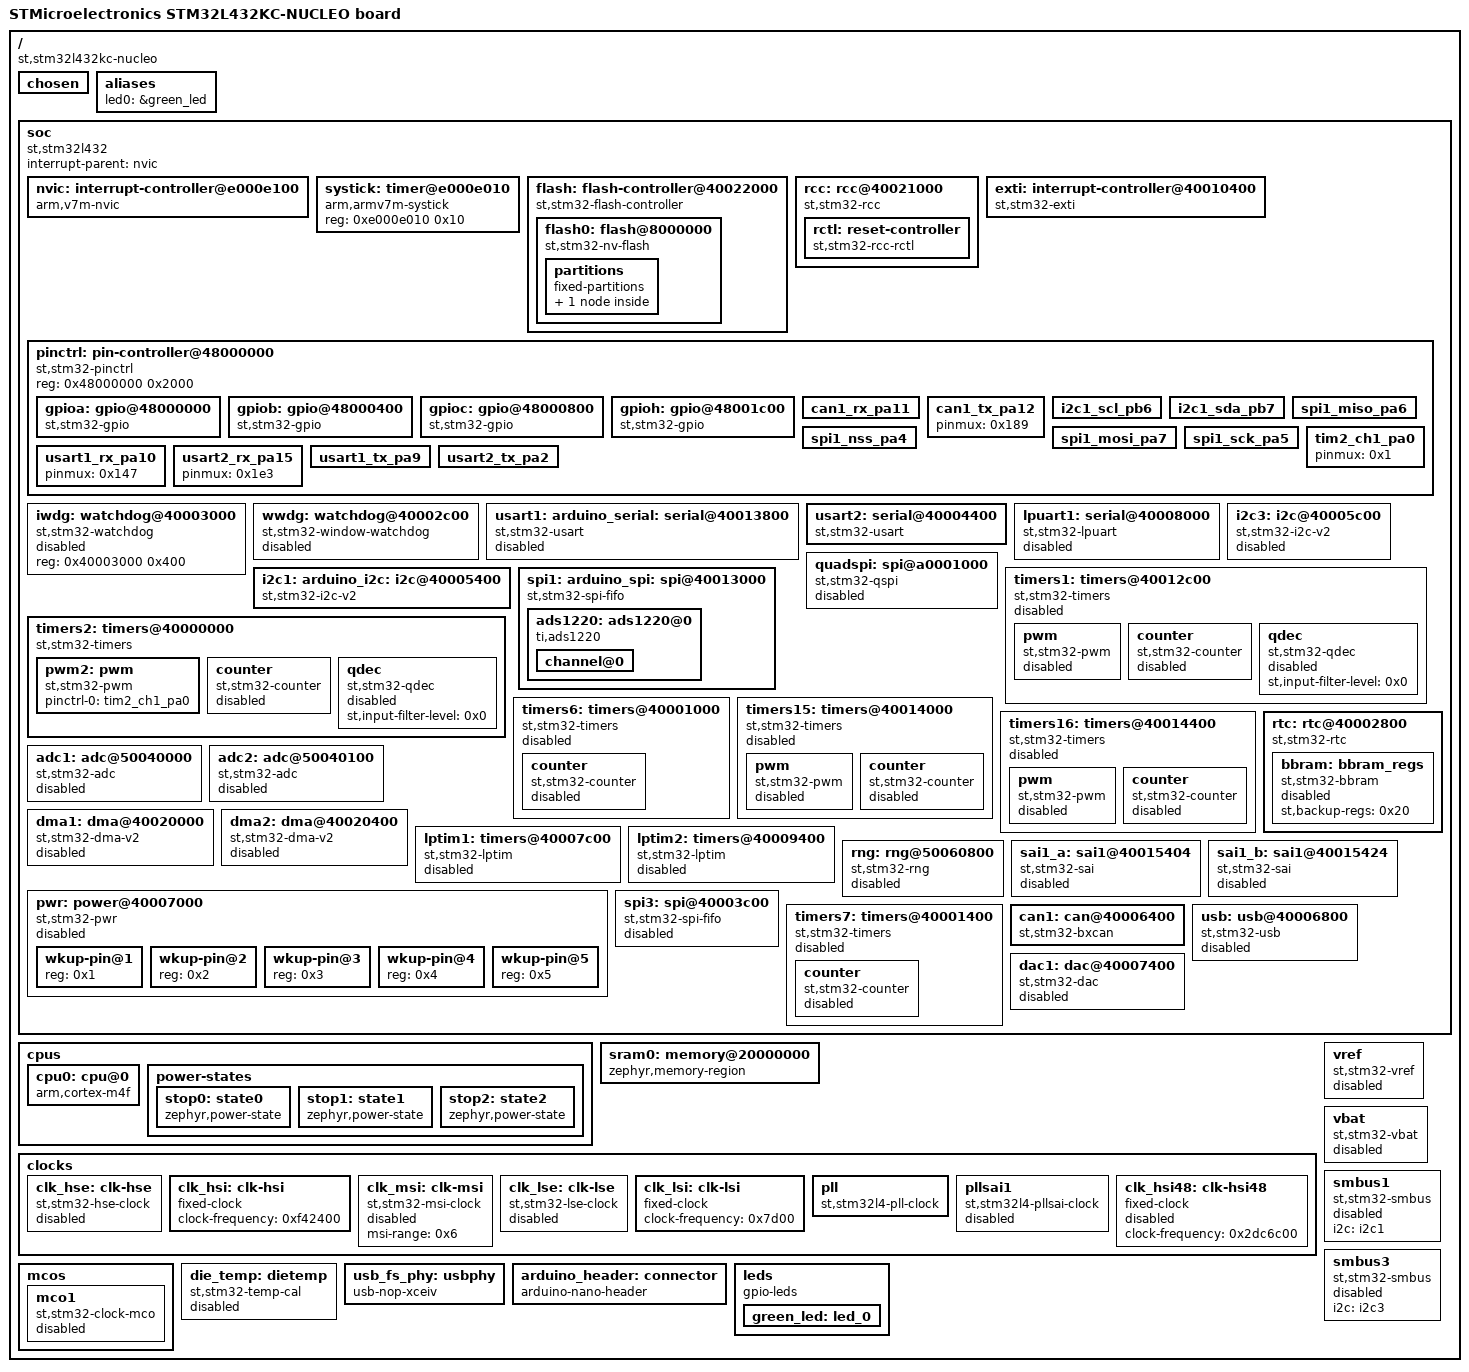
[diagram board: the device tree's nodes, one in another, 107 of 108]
/dts-v1/;

/* node '/' defined in zephyr\dts\common\skeleton.dtsi:9 */
/ {
	#address-cells = < 0x1 >;                              /* in zephyr\dts\common\skeleton.dtsi:10 */
	#size-cells = < 0x1 >;                                 /* in zephyr\dts\common\skeleton.dtsi:11 */
	model = "STMicroelectronics STM32L432KC-NUCLEO board"; /* in zephyr\boards\st\nucleo_l432kc\nucleo_l432kc.dts:13 */
	compatible = "st,stm32l432kc-nucleo";                  /* in zephyr\boards\st\nucleo_l432kc\nucleo_l432kc.dts:14 */

	/* node '/chosen' defined in zephyr\dts\common\skeleton.dtsi:13 */
	chosen {
		zephyr,entropy = &rng;            /* in zephyr\dts\arm\st\l4\stm32l4.dtsi:25 */
		zephyr,flash-controller = &flash; /* in zephyr\dts\arm\st\l4\stm32l4.dtsi:26 */
		zephyr,console = &usart2;         /* in zephyr\boards\st\nucleo_l432kc\nucleo_l432kc.dts:17 */
		zephyr,shell-uart = &usart2;      /* in zephyr\boards\st\nucleo_l432kc\nucleo_l432kc.dts:18 */
		zephyr,sram = &sram0;             /* in zephyr\boards\st\nucleo_l432kc\nucleo_l432kc.dts:19 */
		zephyr,flash = &flash0;           /* in zephyr\boards\st\nucleo_l432kc\nucleo_l432kc.dts:20 */
		zephyr,canbus = &can1;            /* in zephyr\boards\st\nucleo_l432kc\nucleo_l432kc.dts:21 */
	};

	/* node '/aliases' defined in zephyr\dts\common\skeleton.dtsi:15 */
	aliases {
		led0 = &green_led; /* in zephyr\boards\st\nucleo_l432kc\nucleo_l432kc.dts:34 */
	};

	/* node '/soc' defined in zephyr\dts\arm\armv7-m.dtsi:6 */
	soc {
		#address-cells = < 0x1 >;     /* in zephyr\dts\arm\armv7-m.dtsi:7 */
		#size-cells = < 0x1 >;        /* in zephyr\dts\arm\armv7-m.dtsi:8 */
		interrupt-parent = < &nvic >; /* in zephyr\dts\arm\armv7-m.dtsi:10 */
		ranges;                       /* in zephyr\dts\arm\armv7-m.dtsi:11 */
		compatible = "st,stm32l432",
		             "st,stm32l4",
		             "simple-bus";    /* in zephyr\dts\arm\st\l4\stm32l432.dtsi:21 */

		/* node '/soc/interrupt-controller@e000e100' defined in zephyr\dts\arm\armv7-m.dtsi:13 */
		nvic: interrupt-controller@e000e100 {
			#address-cells = < 0x1 >;            /* in zephyr\dts\arm\armv7-m.dtsi:14 */
			compatible = "arm,v7m-nvic";         /* in zephyr\dts\arm\armv7-m.dtsi:15 */
			reg = < 0xe000e100 0xc00 >;          /* in zephyr\dts\arm\armv7-m.dtsi:16 */
			interrupt-controller;                /* in zephyr\dts\arm\armv7-m.dtsi:17 */
			#interrupt-cells = < 0x2 >;          /* in zephyr\dts\arm\armv7-m.dtsi:18 */
			arm,num-irq-priority-bits = < 0x4 >; /* in zephyr\dts\arm\st\l4\stm32l4.dtsi:597 */
			phandle = < 0x1 >;                   /* in zephyr\dts\arm\armv7-m.dtsi:10 */
		};

		/* node '/soc/timer@e000e010' defined in zephyr\dts\arm\armv7-m.dtsi:21 */
		systick: timer@e000e010 {
			compatible = "arm,armv7m-systick"; /* in zephyr\dts\arm\armv7-m.dtsi:22 */
			reg = < 0xe000e010 0x10 >;         /* in zephyr\dts\arm\armv7-m.dtsi:23 */
		};

		/* node '/soc/flash-controller@40022000' defined in zephyr\dts\arm\st\l4\stm32l4.dtsi:126 */
		flash: flash-controller@40022000 {
			compatible = "st,stm32-flash-controller",
			             "st,stm32l4-flash-controller"; /* in zephyr\dts\arm\st\l4\stm32l4.dtsi:127 */
			reg = < 0x40022000 0x400 >;                 /* in zephyr\dts\arm\st\l4\stm32l4.dtsi:128 */
			interrupts = < 0x4 0x0 >;                   /* in zephyr\dts\arm\st\l4\stm32l4.dtsi:129 */
			clocks = < &rcc 0x48 0x100 >;               /* in zephyr\dts\arm\st\l4\stm32l4.dtsi:130 */
			#address-cells = < 0x1 >;                   /* in zephyr\dts\arm\st\l4\stm32l4.dtsi:132 */
			#size-cells = < 0x1 >;                      /* in zephyr\dts\arm\st\l4\stm32l4.dtsi:133 */

			/* node '/soc/flash-controller@40022000/flash@8000000' defined in zephyr\dts\arm\st\l4\stm32l4.dtsi:135 */
			flash0: flash@8000000 {
				compatible = "st,stm32-nv-flash",
				             "soc-nv-flash";      /* in zephyr\dts\arm\st\l4\stm32l4.dtsi:136 */
				write-block-size = < 0x8 >;       /* in zephyr\dts\arm\st\l4\stm32l4.dtsi:138 */
				erase-block-size = < 0x800 >;     /* in zephyr\dts\arm\st\l4\stm32l4.dtsi:139 */
				max-erase-time = < 0x19 >;        /* in zephyr\dts\arm\st\l4\stm32l4.dtsi:141 */
				reg = < 0x8000000 0x40000 >;      /* in zephyr\dts\arm\st\l4\stm32l432Xc.dtsi:16 */

				/* node '/soc/flash-controller@40022000/flash@8000000/partitions' defined in zephyr\boards\st\nucleo_l432kc\nucleo_l432kc.dts:114 */
				partitions {
					compatible = "fixed-partitions"; /* in zephyr\boards\st\nucleo_l432kc\nucleo_l432kc.dts:115 */
					#address-cells = < 0x1 >;        /* in zephyr\boards\st\nucleo_l432kc\nucleo_l432kc.dts:116 */
					#size-cells = < 0x1 >;           /* in zephyr\boards\st\nucleo_l432kc\nucleo_l432kc.dts:117 */

					/* node '/soc/flash-controller@40022000/flash@8000000/partitions/partition@3c000' defined in zephyr\boards\st\nucleo_l432kc\nucleo_l432kc.dts:122 */
					storage_partition: partition@3c000 {
						label = "storage";        /* in zephyr\boards\st\nucleo_l432kc\nucleo_l432kc.dts:123 */
						reg = < 0x3c000 0x4000 >; /* in zephyr\boards\st\nucleo_l432kc\nucleo_l432kc.dts:124 */
					};
				};
			};
		};

		/* node '/soc/rcc@40021000' defined in zephyr\dts\arm\st\l4\stm32l4.dtsi:145 */
		rcc: rcc@40021000 {
			compatible = "st,stm32-rcc";     /* in zephyr\dts\arm\st\l4\stm32l4.dtsi:146 */
			#clock-cells = < 0x2 >;          /* in zephyr\dts\arm\st\l4\stm32l4.dtsi:147 */
			reg = < 0x40021000 0x400 >;      /* in zephyr\dts\arm\st\l4\stm32l4.dtsi:148 */
			clocks = < &pll >;               /* in zephyr\boards\st\nucleo_l432kc\nucleo_l432kc.dts:57 */
			clock-frequency = < 0x4c4b400 >; /* in zephyr\boards\st\nucleo_l432kc\nucleo_l432kc.dts:58 */
			ahb-prescaler = < 0x1 >;         /* in zephyr\boards\st\nucleo_l432kc\nucleo_l432kc.dts:59 */
			apb1-prescaler = < 0x1 >;        /* in zephyr\boards\st\nucleo_l432kc\nucleo_l432kc.dts:60 */
			apb2-prescaler = < 0x1 >;        /* in zephyr\boards\st\nucleo_l432kc\nucleo_l432kc.dts:61 */
			phandle = < 0x2 >;               /* in zephyr\dts\arm\st\l4\stm32l4.dtsi:130 */

			/* node '/soc/rcc@40021000/reset-controller' defined in zephyr\dts\arm\st\l4\stm32l4.dtsi:150 */
			rctl: reset-controller {
				compatible = "st,stm32-rcc-rctl"; /* in zephyr\dts\arm\st\l4\stm32l4.dtsi:151 */
				#reset-cells = < 0x1 >;           /* in zephyr\dts\arm\st\l4\stm32l4.dtsi:152 */
				phandle = < 0x4 >;                /* in zephyr\dts\arm\st\l4\stm32l4.dtsi:229 */
			};
		};

		/* node '/soc/interrupt-controller@40010400' defined in zephyr\dts\arm\st\l4\stm32l4.dtsi:156 */
		exti: interrupt-controller@40010400 {
			compatible = "st,stm32-exti";  /* in zephyr\dts\arm\st\l4\stm32l4.dtsi:157 */
			interrupt-controller;          /* in zephyr\dts\arm\st\l4\stm32l4.dtsi:158 */
			#interrupt-cells = < 0x1 >;    /* in zephyr\dts\arm\st\l4\stm32l4.dtsi:159 */
			#address-cells = < 0x0 >;      /* in zephyr\dts\arm\st\l4\stm32l4.dtsi:160 */
			reg = < 0x40010400 0x400 >;    /* in zephyr\dts\arm\st\l4\stm32l4.dtsi:161 */
			clocks = < &rcc 0x60 0x1 >;    /* in zephyr\dts\arm\st\l4\stm32l4.dtsi:162 */
			num-lines = < 0x40 >;          /* in zephyr\dts\arm\st\l4\stm32l4.dtsi:163 */
			interrupts = < 0x6 0x0 >,
			             < 0x7 0x0 >,
			             < 0x8 0x0 >,
			             < 0x9 0x0 >,
			             < 0xa 0x0 >,
			             < 0x17 0x0 >,
			             < 0x28 0x0 >;     /* in zephyr\dts\arm\st\l4\stm32l4.dtsi:164 */
			interrupt-names = "line0",
			                  "line1",
			                  "line2",
			                  "line3",
			                  "line4",
			                  "line5-9",
			                  "line10-15"; /* in zephyr\dts\arm\st\l4\stm32l4.dtsi:166 */
			line-ranges = < 0x0 0x1 >,
			              < 0x1 0x1 >,
			              < 0x2 0x1 >,
			              < 0x3 0x1 >,
			              < 0x4 0x1 >,
			              < 0x5 0x5 >,
			              < 0xa 0x6 >;     /* in zephyr\dts\arm\st\l4\stm32l4.dtsi:168 */
		};

		/* node '/soc/pin-controller@48000000' defined in zephyr\dts\arm\st\l4\stm32l4.dtsi:172 */
		pinctrl: pin-controller@48000000 {
			compatible = "st,stm32-pinctrl"; /* in zephyr\dts\arm\st\l4\stm32l4.dtsi:173 */
			#address-cells = < 0x1 >;        /* in zephyr\dts\arm\st\l4\stm32l4.dtsi:174 */
			#size-cells = < 0x1 >;           /* in zephyr\dts\arm\st\l4\stm32l4.dtsi:175 */
			reg = < 0x48000000 0x2000 >;     /* in zephyr\dts\arm\st\l4\stm32l4.dtsi:176 */

			/* node '/soc/pin-controller@48000000/gpio@48000000' defined in zephyr\dts\arm\st\l4\stm32l4.dtsi:178 */
			gpioa: gpio@48000000 {
				compatible = "st,stm32-gpio"; /* in zephyr\dts\arm\st\l4\stm32l4.dtsi:179 */
				gpio-controller;              /* in zephyr\dts\arm\st\l4\stm32l4.dtsi:180 */
				#gpio-cells = < 0x2 >;        /* in zephyr\dts\arm\st\l4\stm32l4.dtsi:181 */
				reg = < 0x48000000 0x400 >;   /* in zephyr\dts\arm\st\l4\stm32l4.dtsi:182 */
				clocks = < &rcc 0x4c 0x1 >;   /* in zephyr\dts\arm\st\l4\stm32l4.dtsi:183 */
				phandle = < 0xf >;            /* in miri-tl6-inside-lift\app\boards\nucleo_l432kc.overlay:16 */
			};

			/* node '/soc/pin-controller@48000000/gpio@48000400' defined in zephyr\dts\arm\st\l4\stm32l4.dtsi:186 */
			gpiob: gpio@48000400 {
				compatible = "st,stm32-gpio"; /* in zephyr\dts\arm\st\l4\stm32l4.dtsi:187 */
				gpio-controller;              /* in zephyr\dts\arm\st\l4\stm32l4.dtsi:188 */
				#gpio-cells = < 0x2 >;        /* in zephyr\dts\arm\st\l4\stm32l4.dtsi:189 */
				reg = < 0x48000400 0x400 >;   /* in zephyr\dts\arm\st\l4\stm32l4.dtsi:190 */
				clocks = < &rcc 0x4c 0x2 >;   /* in zephyr\dts\arm\st\l4\stm32l4.dtsi:191 */
				phandle = < 0x1d >;           /* in zephyr\boards\st\nucleo_l432kc\arduino_nano_connector.dtsi:16 */
			};

			/* node '/soc/pin-controller@48000000/gpio@48000800' defined in zephyr\dts\arm\st\l4\stm32l4.dtsi:194 */
			gpioc: gpio@48000800 {
				compatible = "st,stm32-gpio"; /* in zephyr\dts\arm\st\l4\stm32l4.dtsi:195 */
				gpio-controller;              /* in zephyr\dts\arm\st\l4\stm32l4.dtsi:196 */
				#gpio-cells = < 0x2 >;        /* in zephyr\dts\arm\st\l4\stm32l4.dtsi:197 */
				reg = < 0x48000800 0x400 >;   /* in zephyr\dts\arm\st\l4\stm32l4.dtsi:198 */
				clocks = < &rcc 0x4c 0x4 >;   /* in zephyr\dts\arm\st\l4\stm32l4.dtsi:199 */
				phandle = < 0x10 >;           /* in miri-tl6-inside-lift\app\boards\nucleo_l432kc.overlay:24 */
			};

			/* node '/soc/pin-controller@48000000/gpio@48001c00' defined in zephyr\dts\arm\st\l4\stm32l4.dtsi:202 */
			gpioh: gpio@48001c00 {
				compatible = "st,stm32-gpio"; /* in zephyr\dts\arm\st\l4\stm32l4.dtsi:203 */
				gpio-controller;              /* in zephyr\dts\arm\st\l4\stm32l4.dtsi:204 */
				#gpio-cells = < 0x2 >;        /* in zephyr\dts\arm\st\l4\stm32l4.dtsi:205 */
				reg = < 0x48001c00 0x400 >;   /* in zephyr\dts\arm\st\l4\stm32l4.dtsi:206 */
				clocks = < &rcc 0x4c 0x80 >;  /* in zephyr\dts\arm\st\l4\stm32l4.dtsi:207 */
			};

			/* node '/soc/pin-controller@48000000/can1_rx_pa11' defined in modules\hal\stm32\dts\st\l4\stm32l432k(b-c)ux-pinctrl.dtsi:163 */
			can1_rx_pa11: can1_rx_pa11 {
				pinmux = < 0x169 >; /* in modules\hal\stm32\dts\st\l4\stm32l432k(b-c)ux-pinctrl.dtsi:164 */
				bias-pull-up;       /* in modules\hal\stm32\dts\st\l4\stm32l432k(b-c)ux-pinctrl.dtsi:165 */
				phandle = < 0x13 >; /* in zephyr\boards\st\nucleo_l432kc\nucleo_l432kc.dts:102 */
			};

			/* node '/soc/pin-controller@48000000/can1_tx_pa12' defined in modules\hal\stm32\dts\st\l4\stm32l432k(b-c)ux-pinctrl.dtsi:170 */
			can1_tx_pa12: can1_tx_pa12 {
				pinmux = < 0x189 >; /* in modules\hal\stm32\dts\st\l4\stm32l432k(b-c)ux-pinctrl.dtsi:171 */
				phandle = < 0x14 >; /* in zephyr\boards\st\nucleo_l432kc\nucleo_l432kc.dts:102 */
			};

			/* node '/soc/pin-controller@48000000/i2c1_scl_pb6' defined in modules\hal\stm32\dts\st\l4\stm32l432k(b-c)ux-pinctrl.dtsi:276 */
			i2c1_scl_pb6: i2c1_scl_pb6 {
				pinmux = < 0x2c4 >; /* in modules\hal\stm32\dts\st\l4\stm32l432k(b-c)ux-pinctrl.dtsi:277 */
				bias-pull-up;       /* in modules\hal\stm32\dts\st\l4\stm32l432k(b-c)ux-pinctrl.dtsi:278 */
				drive-open-drain;   /* in modules\hal\stm32\dts\st\l4\stm32l432k(b-c)ux-pinctrl.dtsi:279 */
				phandle = < 0x9 >;  /* in zephyr\boards\st\nucleo_l432kc\nucleo_l432kc.dts:85 */
			};

			/* node '/soc/pin-controller@48000000/i2c1_sda_pb7' defined in modules\hal\stm32\dts\st\l4\stm32l432k(b-c)ux-pinctrl.dtsi:296 */
			i2c1_sda_pb7: i2c1_sda_pb7 {
				pinmux = < 0x2e4 >; /* in modules\hal\stm32\dts\st\l4\stm32l432k(b-c)ux-pinctrl.dtsi:297 */
				bias-pull-up;       /* in modules\hal\stm32\dts\st\l4\stm32l432k(b-c)ux-pinctrl.dtsi:298 */
				drive-open-drain;   /* in modules\hal\stm32\dts\st\l4\stm32l432k(b-c)ux-pinctrl.dtsi:299 */
				phandle = < 0xa >;  /* in zephyr\boards\st\nucleo_l432kc\nucleo_l432kc.dts:85 */
			};

			/* node '/soc/pin-controller@48000000/spi1_miso_pa6' defined in modules\hal\stm32\dts\st\l4\stm32l432k(b-c)ux-pinctrl.dtsi:490 */
			spi1_miso_pa6: spi1_miso_pa6 {
				pinmux = < 0xc5 >;             /* in modules\hal\stm32\dts\st\l4\stm32l432k(b-c)ux-pinctrl.dtsi:491 */
				bias-pull-down;                /* in modules\hal\stm32\dts\st\l4\stm32l432k(b-c)ux-pinctrl.dtsi:492 */
				slew-rate = "very-high-speed"; /* in modules\hal\stm32\dts\st\l4\stm32l432k(b-c)ux-pinctrl.dtsi:493 */
				phandle = < 0xd >;             /* in miri-tl6-inside-lift\app\boards\nucleo_l432kc.overlay:11 */
			};

			/* node '/soc/pin-controller@48000000/spi1_mosi_pa7' defined in modules\hal\stm32\dts\st\l4\stm32l432k(b-c)ux-pinctrl.dtsi:516 */
			spi1_mosi_pa7: spi1_mosi_pa7 {
				pinmux = < 0xe5 >;             /* in modules\hal\stm32\dts\st\l4\stm32l432k(b-c)ux-pinctrl.dtsi:517 */
				bias-pull-down;                /* in modules\hal\stm32\dts\st\l4\stm32l432k(b-c)ux-pinctrl.dtsi:518 */
				slew-rate = "very-high-speed"; /* in modules\hal\stm32\dts\st\l4\stm32l432k(b-c)ux-pinctrl.dtsi:519 */
				phandle = < 0xe >;             /* in miri-tl6-inside-lift\app\boards\nucleo_l432kc.overlay:11 */
			};

			/* node '/soc/pin-controller@48000000/spi1_nss_pa4' defined in modules\hal\stm32\dts\st\l4\stm32l432k(b-c)ux-pinctrl.dtsi:542 */
			spi1_nss_pa4: spi1_nss_pa4 {
				pinmux = < 0x85 >;             /* in modules\hal\stm32\dts\st\l4\stm32l432k(b-c)ux-pinctrl.dtsi:543 */
				bias-pull-up;                  /* in modules\hal\stm32\dts\st\l4\stm32l432k(b-c)ux-pinctrl.dtsi:544 */
				slew-rate = "very-high-speed"; /* in modules\hal\stm32\dts\st\l4\stm32l432k(b-c)ux-pinctrl.dtsi:545 */
				phandle = < 0xb >;             /* in miri-tl6-inside-lift\app\boards\nucleo_l432kc.overlay:11 */
			};

			/* node '/soc/pin-controller@48000000/spi1_sck_pa5' defined in modules\hal\stm32\dts\st\l4\stm32l432k(b-c)ux-pinctrl.dtsi:580 */
			spi1_sck_pa5: spi1_sck_pa5 {
				pinmux = < 0xa5 >;             /* in modules\hal\stm32\dts\st\l4\stm32l432k(b-c)ux-pinctrl.dtsi:581 */
				bias-pull-down;                /* in modules\hal\stm32\dts\st\l4\stm32l432k(b-c)ux-pinctrl.dtsi:582 */
				slew-rate = "very-high-speed"; /* in modules\hal\stm32\dts\st\l4\stm32l432k(b-c)ux-pinctrl.dtsi:583 */
				phandle = < 0xc >;             /* in miri-tl6-inside-lift\app\boards\nucleo_l432kc.overlay:11 */
			};

			/* node '/soc/pin-controller@48000000/tim2_ch1_pa0' defined in modules\hal\stm32\dts\st\l4\stm32l432k(b-c)ux-pinctrl.dtsi:646 */
			tim2_ch1_pa0: tim2_ch1_pa0 {
				pinmux = < 0x1 >;   /* in modules\hal\stm32\dts\st\l4\stm32l432k(b-c)ux-pinctrl.dtsi:647 */
				phandle = < 0x11 >; /* in zephyr\boards\st\nucleo_l432kc\nucleo_l432kc.dts:96 */
			};

			/* node '/soc/pin-controller@48000000/usart1_rx_pa10' defined in modules\hal\stm32\dts\st\l4\stm32l432k(b-c)ux-pinctrl.dtsi:784 */
			usart1_rx_pa10: usart1_rx_pa10 {
				pinmux = < 0x147 >; /* in modules\hal\stm32\dts\st\l4\stm32l432k(b-c)ux-pinctrl.dtsi:785 */
				phandle = < 0x6 >;  /* in zephyr\boards\st\nucleo_l432kc\nucleo_l432kc.dts:65 */
			};

			/* node '/soc/pin-controller@48000000/usart2_rx_pa15' defined in modules\hal\stm32\dts\st\l4\stm32l432k(b-c)ux-pinctrl.dtsi:796 */
			usart2_rx_pa15: usart2_rx_pa15 {
				pinmux = < 0x1e3 >; /* in modules\hal\stm32\dts\st\l4\stm32l432k(b-c)ux-pinctrl.dtsi:797 */
				phandle = < 0x8 >;  /* in zephyr\boards\st\nucleo_l432kc\nucleo_l432kc.dts:71 */
			};

			/* node '/soc/pin-controller@48000000/usart1_tx_pa9' defined in modules\hal\stm32\dts\st\l4\stm32l432k(b-c)ux-pinctrl.dtsi:807 */
			usart1_tx_pa9: usart1_tx_pa9 {
				pinmux = < 0x127 >; /* in modules\hal\stm32\dts\st\l4\stm32l432k(b-c)ux-pinctrl.dtsi:808 */
				bias-pull-up;       /* in modules\hal\stm32\dts\st\l4\stm32l432k(b-c)ux-pinctrl.dtsi:809 */
				phandle = < 0x5 >;  /* in zephyr\boards\st\nucleo_l432kc\nucleo_l432kc.dts:65 */
			};

			/* node '/soc/pin-controller@48000000/usart2_tx_pa2' defined in modules\hal\stm32\dts\st\l4\stm32l432k(b-c)ux-pinctrl.dtsi:817 */
			usart2_tx_pa2: usart2_tx_pa2 {
				pinmux = < 0x47 >; /* in modules\hal\stm32\dts\st\l4\stm32l432k(b-c)ux-pinctrl.dtsi:818 */
				bias-pull-up;      /* in modules\hal\stm32\dts\st\l4\stm32l432k(b-c)ux-pinctrl.dtsi:819 */
				phandle = < 0x7 >; /* in zephyr\boards\st\nucleo_l432kc\nucleo_l432kc.dts:71 */
			};
		};

		/* node '/soc/watchdog@40003000' defined in zephyr\dts\arm\st\l4\stm32l4.dtsi:211 */
		iwdg: watchdog@40003000 {
			compatible = "st,stm32-watchdog"; /* in zephyr\dts\arm\st\l4\stm32l4.dtsi:212 */
			reg = < 0x40003000 0x400 >;       /* in zephyr\dts\arm\st\l4\stm32l4.dtsi:213 */
			status = "disabled";              /* in zephyr\dts\arm\st\l4\stm32l4.dtsi:214 */
		};

		/* node '/soc/watchdog@40002c00' defined in zephyr\dts\arm\st\l4\stm32l4.dtsi:217 */
		wwdg: watchdog@40002c00 {
			compatible = "st,stm32-window-watchdog"; /* in zephyr\dts\arm\st\l4\stm32l4.dtsi:218 */
			reg = < 0x40002c00 0x400 >;              /* in zephyr\dts\arm\st\l4\stm32l4.dtsi:219 */
			clocks = < &rcc 0x58 0x800 >;            /* in zephyr\dts\arm\st\l4\stm32l4.dtsi:220 */
			interrupts = < 0x0 0x7 >;                /* in zephyr\dts\arm\st\l4\stm32l4.dtsi:221 */
			status = "disabled";                     /* in zephyr\dts\arm\st\l4\stm32l4.dtsi:222 */
		};

		/* node '/soc/serial@40013800' defined in zephyr\dts\arm\st\l4\stm32l4.dtsi:225 */
		usart1: arduino_serial: serial@40013800 {
			compatible = "st,stm32-usart",
			             "st,stm32-uart";                   /* in zephyr\dts\arm\st\l4\stm32l4.dtsi:226 */
			reg = < 0x40013800 0x400 >;                     /* in zephyr\dts\arm\st\l4\stm32l4.dtsi:227 */
			clocks = < &rcc 0x60 0x4000 >;                  /* in zephyr\dts\arm\st\l4\stm32l4.dtsi:228 */
			resets = < &rctl 0x80e >;                       /* in zephyr\dts\arm\st\l4\stm32l4.dtsi:229 */
			interrupts = < 0x25 0x0 >;                      /* in zephyr\dts\arm\st\l4\stm32l4.dtsi:230 */
			status = "disabled";                            /* in zephyr\dts\arm\st\l4\stm32l4.dtsi:231 */
			pinctrl-0 = < &usart1_tx_pa9 &usart1_rx_pa10 >; /* in zephyr\boards\st\nucleo_l432kc\nucleo_l432kc.dts:65 */
			pinctrl-names = "default";                      /* in zephyr\boards\st\nucleo_l432kc\nucleo_l432kc.dts:66 */
			current-speed = < 0x1c200 >;                    /* in zephyr\boards\st\nucleo_l432kc\nucleo_l432kc.dts:67 */
		};

		/* node '/soc/serial@40004400' defined in zephyr\dts\arm\st\l4\stm32l4.dtsi:234 */
		usart2: serial@40004400 {
			compatible = "st,stm32-usart",
			             "st,stm32-uart";                   /* in zephyr\dts\arm\st\l4\stm32l4.dtsi:235 */
			reg = < 0x40004400 0x400 >;                     /* in zephyr\dts\arm\st\l4\stm32l4.dtsi:236 */
			clocks = < &rcc 0x58 0x20000 >;                 /* in zephyr\dts\arm\st\l4\stm32l4.dtsi:237 */
			resets = < &rctl 0x711 >;                       /* in zephyr\dts\arm\st\l4\stm32l4.dtsi:238 */
			interrupts = < 0x26 0x0 >;                      /* in zephyr\dts\arm\st\l4\stm32l4.dtsi:239 */
			pinctrl-0 = < &usart2_tx_pa2 &usart2_rx_pa15 >; /* in zephyr\boards\st\nucleo_l432kc\nucleo_l432kc.dts:71 */
			pinctrl-names = "default";                      /* in zephyr\boards\st\nucleo_l432kc\nucleo_l432kc.dts:72 */
			current-speed = < 0x1c200 >;                    /* in zephyr\boards\st\nucleo_l432kc\nucleo_l432kc.dts:73 */
			status = "okay";                                /* in zephyr\boards\st\nucleo_l432kc\nucleo_l432kc.dts:74 */
		};

		/* node '/soc/serial@40008000' defined in zephyr\dts\arm\st\l4\stm32l4.dtsi:243 */
		lpuart1: serial@40008000 {
			compatible = "st,stm32-lpuart",
			             "st,stm32-uart";   /* in zephyr\dts\arm\st\l4\stm32l4.dtsi:244 */
			reg = < 0x40008000 0x400 >;     /* in zephyr\dts\arm\st\l4\stm32l4.dtsi:245 */
			clocks = < &rcc 0x5c 0x1 >;     /* in zephyr\dts\arm\st\l4\stm32l4.dtsi:246 */
			resets = < &rctl 0x780 >;       /* in zephyr\dts\arm\st\l4\stm32l4.dtsi:247 */
			interrupts = < 0x46 0x0 >;      /* in zephyr\dts\arm\st\l4\stm32l4.dtsi:248 */
			status = "disabled";            /* in zephyr\dts\arm\st\l4\stm32l4.dtsi:249 */
		};

		/* node '/soc/i2c@40005400' defined in zephyr\dts\arm\st\l4\stm32l4.dtsi:252 */
		i2c1: arduino_i2c: i2c@40005400 {
			compatible = "st,stm32-i2c-v2";              /* in zephyr\dts\arm\st\l4\stm32l4.dtsi:253 */
			#address-cells = < 0x1 >;                    /* in zephyr\dts\arm\st\l4\stm32l4.dtsi:255 */
			#size-cells = < 0x0 >;                       /* in zephyr\dts\arm\st\l4\stm32l4.dtsi:256 */
			reg = < 0x40005400 0x400 >;                  /* in zephyr\dts\arm\st\l4\stm32l4.dtsi:257 */
			clocks = < &rcc 0x58 0x200000 >;             /* in zephyr\dts\arm\st\l4\stm32l4.dtsi:258 */
			interrupts = < 0x1f 0x0 >,
			             < 0x20 0x0 >;                   /* in zephyr\dts\arm\st\l4\stm32l4.dtsi:259 */
			interrupt-names = "event",
			                  "error";                   /* in zephyr\dts\arm\st\l4\stm32l4.dtsi:260 */
			pinctrl-0 = < &i2c1_scl_pb6 &i2c1_sda_pb7 >; /* in zephyr\boards\st\nucleo_l432kc\nucleo_l432kc.dts:85 */
			pinctrl-names = "default";                   /* in zephyr\boards\st\nucleo_l432kc\nucleo_l432kc.dts:86 */
			clock-frequency = < 0x61a80 >;               /* in zephyr\boards\st\nucleo_l432kc\nucleo_l432kc.dts:87 */
			status = "okay";                             /* in zephyr\boards\st\nucleo_l432kc\nucleo_l432kc.dts:88 */
			phandle = < 0x1b >;                          /* in zephyr\dts\arm\st\l4\stm32l4.dtsi:583 */
		};

		/* node '/soc/i2c@40005c00' defined in zephyr\dts\arm\st\l4\stm32l4.dtsi:264 */
		i2c3: i2c@40005c00 {
			compatible = "st,stm32-i2c-v2";  /* in zephyr\dts\arm\st\l4\stm32l4.dtsi:265 */
			clock-frequency = < 0x186a0 >;   /* in zephyr\dts\arm\st\l4\stm32l4.dtsi:266 */
			#address-cells = < 0x1 >;        /* in zephyr\dts\arm\st\l4\stm32l4.dtsi:267 */
			#size-cells = < 0x0 >;           /* in zephyr\dts\arm\st\l4\stm32l4.dtsi:268 */
			reg = < 0x40005c00 0x400 >;      /* in zephyr\dts\arm\st\l4\stm32l4.dtsi:269 */
			clocks = < &rcc 0x58 0x800000 >; /* in zephyr\dts\arm\st\l4\stm32l4.dtsi:270 */
			interrupts = < 0x48 0x0 >,
			             < 0x49 0x0 >;       /* in zephyr\dts\arm\st\l4\stm32l4.dtsi:271 */
			interrupt-names = "event",
			                  "error";       /* in zephyr\dts\arm\st\l4\stm32l4.dtsi:272 */
			status = "disabled";             /* in zephyr\dts\arm\st\l4\stm32l4.dtsi:273 */
			phandle = < 0x1c >;              /* in zephyr\dts\arm\st\l4\stm32l4.dtsi:591 */
		};

		/* node '/soc/spi@a0001000' defined in zephyr\dts\arm\st\l4\stm32l4.dtsi:276 */
		quadspi: spi@a0001000 {
			compatible = "st,stm32-qspi";    /* in zephyr\dts\arm\st\l4\stm32l4.dtsi:277 */
			#address-cells = < 0x1 >;        /* in zephyr\dts\arm\st\l4\stm32l4.dtsi:278 */
			#size-cells = < 0x0 >;           /* in zephyr\dts\arm\st\l4\stm32l4.dtsi:279 */
			reg = < 0xa0001000 0x400 >,
			      < 0x90000000 0x10000000 >; /* in zephyr\dts\arm\st\l4\stm32l4.dtsi:280 */
			interrupts = < 0x47 0x0 >;       /* in zephyr\dts\arm\st\l4\stm32l4.dtsi:281 */
			clocks = < &rcc 0x50 0x100 >;    /* in zephyr\dts\arm\st\l4\stm32l4.dtsi:282 */
			status = "disabled";             /* in zephyr\dts\arm\st\l4\stm32l4.dtsi:283 */
		};

		/* node '/soc/spi@40013000' defined in zephyr\dts\arm\st\l4\stm32l4.dtsi:286 */
		spi1: arduino_spi: spi@40013000 {
			compatible = "st,stm32-spi-fifo",
			             "st,stm32-spi";                                               /* in zephyr\dts\arm\st\l4\stm32l4.dtsi:287 */
			#address-cells = < 0x1 >;                                                  /* in zephyr\dts\arm\st\l4\stm32l4.dtsi:288 */
			#size-cells = < 0x0 >;                                                     /* in zephyr\dts\arm\st\l4\stm32l4.dtsi:289 */
			reg = < 0x40013000 0x400 >;                                                /* in zephyr\dts\arm\st\l4\stm32l4.dtsi:290 */
			interrupts = < 0x23 0x5 >;                                                 /* in zephyr\dts\arm\st\l4\stm32l4.dtsi:291 */
			clocks = < &rcc 0x60 0x1000 >;                                             /* in zephyr\dts\arm\st\l4\stm32l4.dtsi:292 */
			st,spi-data-width = "full-4-to-16-bit";                                    /* in zephyr\dts\arm\st\l4\stm32l4.dtsi:293 */
			status = "okay";                                                           /* in miri-tl6-inside-lift\app\boards\nucleo_l432kc.overlay:8 */
			pinctrl-0 = < &spi1_nss_pa4 &spi1_sck_pa5 &spi1_miso_pa6 &spi1_mosi_pa7 >; /* in miri-tl6-inside-lift\app\boards\nucleo_l432kc.overlay:11 */
			pinctrl-names = "default";                                                 /* in miri-tl6-inside-lift\app\boards\nucleo_l432kc.overlay:13 */
			cs-gpios = < &gpioa 0x4 0x1 >;                                             /* in miri-tl6-inside-lift\app\boards\nucleo_l432kc.overlay:16 */

			/* node '/soc/spi@40013000/ads1220@0' defined in miri-tl6-inside-lift\app\boards\nucleo_l432kc.overlay:18 */
			ads1220: ads1220@0 {
				compatible = "ti,ads1220";       /* in miri-tl6-inside-lift\app\boards\nucleo_l432kc.overlay:19 */
				reg = < 0x0 >;                   /* in miri-tl6-inside-lift\app\boards\nucleo_l432kc.overlay:20 */
				spi-max-frequency = < 0xf4240 >; /* in miri-tl6-inside-lift\app\boards\nucleo_l432kc.overlay:21 */
				drdy-gpios = < &gpioc 0x9 0x1 >; /* in miri-tl6-inside-lift\app\boards\nucleo_l432kc.overlay:24 */
				#io-channel-cells = < 0x1 >;     /* in miri-tl6-inside-lift\app\boards\nucleo_l432kc.overlay:26 */
				#address-cells = < 0x1 >;        /* in miri-tl6-inside-lift\app\boards\nucleo_l432kc.overlay:27 */
				#size-cells = < 0x0 >;           /* in miri-tl6-inside-lift\app\boards\nucleo_l432kc.overlay:28 */

				/* node '/soc/spi@40013000/ads1220@0/channel@0' defined in miri-tl6-inside-lift\app\boards\nucleo_l432kc.overlay:30 */
				channel@0 {
					reg = < 0x0 >;                         /* in miri-tl6-inside-lift\app\boards\nucleo_l432kc.overlay:31 */
					zephyr,gain = "ADC_GAIN_1";            /* in miri-tl6-inside-lift\app\boards\nucleo_l432kc.overlay:32 */
					zephyr,reference = "ADC_REF_INTERNAL"; /* in miri-tl6-inside-lift\app\boards\nucleo_l432kc.overlay:33 */
					zephyr,acquisition-time = < 0x0 >;     /* in miri-tl6-inside-lift\app\boards\nucleo_l432kc.overlay:34 */
				};
			};
		};

		/* node '/soc/timers@40012c00' defined in zephyr\dts\arm\st\l4\stm32l4.dtsi:297 */
		timers1: timers@40012c00 {
			compatible = "st,stm32-timers"; /* in zephyr\dts\arm\st\l4\stm32l4.dtsi:298 */
			reg = < 0x40012c00 0x400 >;     /* in zephyr\dts\arm\st\l4\stm32l4.dtsi:299 */
			clocks = < &rcc 0x60 0x800 >,
			         < &rcc 0x9 0xff >;     /* in zephyr\dts\arm\st\l4\stm32l4.dtsi:300 */
			resets = < &rctl 0x80b >;       /* in zephyr\dts\arm\st\l4\stm32l4.dtsi:302 */
			interrupts = < 0x18 0x0 >,
			             < 0x19 0x0 >,
			             < 0x1a 0x0 >,
			             < 0x1b 0x0 >;      /* in zephyr\dts\arm\st\l4\stm32l4.dtsi:303 */
			interrupt-names = "brk",
			                  "up",
			                  "trgcom",
			                  "cc";         /* in zephyr\dts\arm\st\l4\stm32l4.dtsi:304 */
			st,prescaler = < 0x0 >;         /* in zephyr\dts\arm\st\l4\stm32l4.dtsi:305 */
			status = "disabled";            /* in zephyr\dts\arm\st\l4\stm32l4.dtsi:306 */

			/* node '/soc/timers@40012c00/pwm' defined in zephyr\dts\arm\st\l4\stm32l4.dtsi:308 */
			pwm {
				compatible = "st,stm32-pwm"; /* in zephyr\dts\arm\st\l4\stm32l4.dtsi:309 */
				status = "disabled";         /* in zephyr\dts\arm\st\l4\stm32l4.dtsi:310 */
				#pwm-cells = < 0x3 >;        /* in zephyr\dts\arm\st\l4\stm32l4.dtsi:311 */
			};

			/* node '/soc/timers@40012c00/counter' defined in zephyr\dts\arm\st\l4\stm32l4.dtsi:314 */
			counter {
				compatible = "st,stm32-counter"; /* in zephyr\dts\arm\st\l4\stm32l4.dtsi:315 */
				status = "disabled";             /* in zephyr\dts\arm\st\l4\stm32l4.dtsi:316 */
			};

			/* node '/soc/timers@40012c00/qdec' defined in zephyr\dts\arm\st\l4\stm32l4.dtsi:319 */
			qdec {
				compatible = "st,stm32-qdec";    /* in zephyr\dts\arm\st\l4\stm32l4.dtsi:320 */
				st,input-filter-level = < 0x0 >; /* in zephyr\dts\arm\st\l4\stm32l4.dtsi:321 */
				status = "disabled";             /* in zephyr\dts\arm\st\l4\stm32l4.dtsi:322 */
			};
		};

		/* node '/soc/timers@40000000' defined in zephyr\dts\arm\st\l4\stm32l4.dtsi:326 */
		timers2: timers@40000000 {
			compatible = "st,stm32-timers"; /* in zephyr\dts\arm\st\l4\stm32l4.dtsi:327 */
			reg = < 0x40000000 0x400 >;     /* in zephyr\dts\arm\st\l4\stm32l4.dtsi:328 */
			clocks = < &rcc 0x58 0x1 >,
			         < &rcc 0x8 0xff >;     /* in zephyr\dts\arm\st\l4\stm32l4.dtsi:329 */
			resets = < &rctl 0x700 >;       /* in zephyr\dts\arm\st\l4\stm32l4.dtsi:331 */
			interrupts = < 0x1c 0x0 >;      /* in zephyr\dts\arm\st\l4\stm32l4.dtsi:332 */
			interrupt-names = "global";     /* in zephyr\dts\arm\st\l4\stm32l4.dtsi:333 */
			st,prescaler = < 0x0 >;         /* in zephyr\dts\arm\st\l4\stm32l4.dtsi:334 */
			status = "okay";                /* in zephyr\boards\st\nucleo_l432kc\nucleo_l432kc.dts:92 */

			/* node '/soc/timers@40000000/pwm' defined in zephyr\dts\arm\st\l4\stm32l4.dtsi:337 */
			pwm2: pwm {
				compatible = "st,stm32-pwm";   /* in zephyr\dts\arm\st\l4\stm32l4.dtsi:338 */
				#pwm-cells = < 0x3 >;          /* in zephyr\dts\arm\st\l4\stm32l4.dtsi:340 */
				status = "okay";               /* in zephyr\boards\st\nucleo_l432kc\nucleo_l432kc.dts:95 */
				pinctrl-0 = < &tim2_ch1_pa0 >; /* in zephyr\boards\st\nucleo_l432kc\nucleo_l432kc.dts:96 */
				pinctrl-names = "default";     /* in zephyr\boards\st\nucleo_l432kc\nucleo_l432kc.dts:97 */
			};

			/* node '/soc/timers@40000000/counter' defined in zephyr\dts\arm\st\l4\stm32l4.dtsi:343 */
			counter {
				compatible = "st,stm32-counter"; /* in zephyr\dts\arm\st\l4\stm32l4.dtsi:344 */
				status = "disabled";             /* in zephyr\dts\arm\st\l4\stm32l4.dtsi:345 */
			};

			/* node '/soc/timers@40000000/qdec' defined in zephyr\dts\arm\st\l4\stm32l4.dtsi:348 */
			qdec {
				compatible = "st,stm32-qdec";    /* in zephyr\dts\arm\st\l4\stm32l4.dtsi:349 */
				st,input-filter-level = < 0x0 >; /* in zephyr\dts\arm\st\l4\stm32l4.dtsi:350 */
				status = "disabled";             /* in zephyr\dts\arm\st\l4\stm32l4.dtsi:351 */
			};
		};

		/* node '/soc/timers@40001000' defined in zephyr\dts\arm\st\l4\stm32l4.dtsi:355 */
		timers6: timers@40001000 {
			compatible = "st,stm32-timers"; /* in zephyr\dts\arm\st\l4\stm32l4.dtsi:356 */
			reg = < 0x40001000 0x400 >;     /* in zephyr\dts\arm\st\l4\stm32l4.dtsi:357 */
			clocks = < &rcc 0x58 0x10 >,
			         < &rcc 0x8 0xff >;     /* in zephyr\dts\arm\st\l4\stm32l4.dtsi:358 */
			resets = < &rctl 0x704 >;       /* in zephyr\dts\arm\st\l4\stm32l4.dtsi:360 */
			interrupts = < 0x36 0x0 >;      /* in zephyr\dts\arm\st\l4\stm32l4.dtsi:361 */
			interrupt-names = "global";     /* in zephyr\dts\arm\st\l4\stm32l4.dtsi:362 */
			st,prescaler = < 0x0 >;         /* in zephyr\dts\arm\st\l4\stm32l4.dtsi:363 */
			status = "disabled";            /* in zephyr\dts\arm\st\l4\stm32l4.dtsi:364 */

			/* node '/soc/timers@40001000/counter' defined in zephyr\dts\arm\st\l4\stm32l4.dtsi:366 */
			counter {
				compatible = "st,stm32-counter"; /* in zephyr\dts\arm\st\l4\stm32l4.dtsi:367 */
				status = "disabled";             /* in zephyr\dts\arm\st\l4\stm32l4.dtsi:368 */
			};
		};

		/* node '/soc/timers@40014000' defined in zephyr\dts\arm\st\l4\stm32l4.dtsi:372 */
		timers15: timers@40014000 {
			compatible = "st,stm32-timers"; /* in zephyr\dts\arm\st\l4\stm32l4.dtsi:373 */
			reg = < 0x40014000 0x400 >;     /* in zephyr\dts\arm\st\l4\stm32l4.dtsi:374 */
			clocks = < &rcc 0x60 0x10000 >,
			         < &rcc 0x9 0xff >;     /* in zephyr\dts\arm\st\l4\stm32l4.dtsi:375 */
			resets = < &rctl 0x810 >;       /* in zephyr\dts\arm\st\l4\stm32l4.dtsi:377 */
			interrupts = < 0x18 0x0 >;      /* in zephyr\dts\arm\st\l4\stm32l4.dtsi:378 */
			interrupt-names = "global";     /* in zephyr\dts\arm\st\l4\stm32l4.dtsi:379 */
			st,prescaler = < 0x0 >;         /* in zephyr\dts\arm\st\l4\stm32l4.dtsi:380 */
			status = "disabled";            /* in zephyr\dts\arm\st\l4\stm32l4.dtsi:381 */

			/* node '/soc/timers@40014000/pwm' defined in zephyr\dts\arm\st\l4\stm32l4.dtsi:383 */
			pwm {
				compatible = "st,stm32-pwm"; /* in zephyr\dts\arm\st\l4\stm32l4.dtsi:384 */
				status = "disabled";         /* in zephyr\dts\arm\st\l4\stm32l4.dtsi:385 */
				#pwm-cells = < 0x3 >;        /* in zephyr\dts\arm\st\l4\stm32l4.dtsi:386 */
			};

			/* node '/soc/timers@40014000/counter' defined in zephyr\dts\arm\st\l4\stm32l4.dtsi:389 */
			counter {
				compatible = "st,stm32-counter"; /* in zephyr\dts\arm\st\l4\stm32l4.dtsi:390 */
				status = "disabled";             /* in zephyr\dts\arm\st\l4\stm32l4.dtsi:391 */
			};
		};

		/* node '/soc/timers@40014400' defined in zephyr\dts\arm\st\l4\stm32l4.dtsi:395 */
		timers16: timers@40014400 {
			compatible = "st,stm32-timers"; /* in zephyr\dts\arm\st\l4\stm32l4.dtsi:396 */
			reg = < 0x40014400 0x400 >;     /* in zephyr\dts\arm\st\l4\stm32l4.dtsi:397 */
			clocks = < &rcc 0x60 0x20000 >,
			         < &rcc 0x9 0xff >;     /* in zephyr\dts\arm\st\l4\stm32l4.dtsi:398 */
			resets = < &rctl 0x811 >;       /* in zephyr\dts\arm\st\l4\stm32l4.dtsi:400 */
			interrupts = < 0x19 0x0 >;      /* in zephyr\dts\arm\st\l4\stm32l4.dtsi:401 */
			interrupt-names = "global";     /* in zephyr\dts\arm\st\l4\stm32l4.dtsi:402 */
			st,prescaler = < 0x0 >;         /* in zephyr\dts\arm\st\l4\stm32l4.dtsi:403 */
			status = "disabled";            /* in zephyr\dts\arm\st\l4\stm32l4.dtsi:404 */

			/* node '/soc/timers@40014400/pwm' defined in zephyr\dts\arm\st\l4\stm32l4.dtsi:406 */
			pwm {
				compatible = "st,stm32-pwm"; /* in zephyr\dts\arm\st\l4\stm32l4.dtsi:407 */
				status = "disabled";         /* in zephyr\dts\arm\st\l4\stm32l4.dtsi:408 */
				#pwm-cells = < 0x3 >;        /* in zephyr\dts\arm\st\l4\stm32l4.dtsi:409 */
			};

			/* node '/soc/timers@40014400/counter' defined in zephyr\dts\arm\st\l4\stm32l4.dtsi:412 */
			counter {
				compatible = "st,stm32-counter"; /* in zephyr\dts\arm\st\l4\stm32l4.dtsi:413 */
				status = "disabled";             /* in zephyr\dts\arm\st\l4\stm32l4.dtsi:414 */
			};
		};

		/* node '/soc/rtc@40002800' defined in zephyr\dts\arm\st\l4\stm32l4.dtsi:418 */
		rtc: rtc@40002800 {
			compatible = "st,stm32-rtc";       /* in zephyr\dts\arm\st\l4\stm32l4.dtsi:419 */
			reg = < 0x40002800 0x400 >;        /* in zephyr\dts\arm\st\l4\stm32l4.dtsi:420 */
			interrupts = < 0x29 0x0 >;         /* in zephyr\dts\arm\st\l4\stm32l4.dtsi:421 */
			prescaler = < 0x8000 >;            /* in zephyr\dts\arm\st\l4\stm32l4.dtsi:423 */
			alarms-count = < 0x2 >;            /* in zephyr\dts\arm\st\l4\stm32l4.dtsi:424 */
			alrm-exti-line = < 0x12 >;         /* in zephyr\dts\arm\st\l4\stm32l4.dtsi:425 */
			clocks = < &rcc 0x58 0x10000000 >,
			         < &rcc 0x3 0x2280090 >;   /* in zephyr\boards\st\nucleo_l432kc\nucleo_l432kc.dts:108 */
			status = "okay";                   /* in zephyr\boards\st\nucleo_l432kc\nucleo_l432kc.dts:110 */

			/* node '/soc/rtc@40002800/bbram_regs' defined in zephyr\dts\arm\st\l4\stm32l432.dtsi:88 */
			bbram: bbram_regs {
				compatible = "st,stm32-bbram"; /* in zephyr\dts\arm\st\l4\stm32l432.dtsi:89 */
				st,backup-regs = < 0x20 >;     /* in zephyr\dts\arm\st\l4\stm32l432.dtsi:90 */
				status = "disabled";           /* in zephyr\dts\arm\st\l4\stm32l432.dtsi:91 */
			};
		};

		/* node '/soc/adc@50040000' defined in zephyr\dts\arm\st\l4\stm32l4.dtsi:429 */
		adc1: adc@50040000 {
			compatible = "st,stm32-adc";                                /* in zephyr\dts\arm\st\l4\stm32l4.dtsi:430 */
			reg = < 0x50040000 0x100 >;                                 /* in zephyr\dts\arm\st\l4\stm32l4.dtsi:431 */
			clocks = < &rcc 0x4c 0x2000 >;                              /* in zephyr\dts\arm\st\l4\stm32l4.dtsi:432 */
			clock-names = "adcx";                                       /* in zephyr\dts\arm\st\l4\stm32l4.dtsi:433 */
			interrupts = < 0x12 0x0 >;                                  /* in zephyr\dts\arm\st\l4\stm32l4.dtsi:434 */
			#io-channel-cells = < 0x1 >;                                /* in zephyr\dts\arm\st\l4\stm32l4.dtsi:435 */
			st,adc-resolutions = < 0xc 0xa 0x8 0x6 >;                   /* in zephyr\dts\arm\st\l4\stm32l4.dtsi:436 */
			sampling-times = < 0x3 0x7 0xd 0x19 0x30 0x5d 0xf8 0x281 >; /* in zephyr\dts\arm\st\l4\stm32l4.dtsi:437 */
			st,adc-sequencer = "programmable";                          /* in zephyr\dts\arm\st\l4\stm32l4.dtsi:438 */
			st,adc-oversampler = "minimal";                             /* in zephyr\dts\arm\st\l4\stm32l4.dtsi:439 */
			st,adc-internal-regulator = "startup-sw-delay";             /* in zephyr\dts\arm\st\l4\stm32l4.dtsi:440 */
			st,adc-has-deep-powerdown;                                  /* in zephyr\dts\arm\st\l4\stm32l4.dtsi:441 */
			st,adc-has-differential-support;                            /* in zephyr\dts\arm\st\l4\stm32l4.dtsi:442 */
			status = "disabled";                                        /* in zephyr\dts\arm\st\l4\stm32l4.dtsi:443 */
			phandle = < 0x1a >;                                         /* in zephyr\dts\arm\st\l4\stm32l4.dtsi:560 */
		};

		/* node '/soc/adc@50040100' defined in zephyr\dts\arm\st\l4\stm32l4.dtsi:446 */
		adc2: adc@50040100 {
			compatible = "st,stm32-adc";                                /* in zephyr\dts\arm\st\l4\stm32l4.dtsi:447 */
			reg = < 0x50040100 0x100 >;                                 /* in zephyr\dts\arm\st\l4\stm32l4.dtsi:448 */
			clocks = < &rcc 0x4c 0x2000 >;                              /* in zephyr\dts\arm\st\l4\stm32l4.dtsi:449 */
			clock-names = "adcx";                                       /* in zephyr\dts\arm\st\l4\stm32l4.dtsi:450 */
			interrupts = < 0x12 0x0 >;                                  /* in zephyr\dts\arm\st\l4\stm32l4.dtsi:451 */
			#io-channel-cells = < 0x1 >;                                /* in zephyr\dts\arm\st\l4\stm32l4.dtsi:452 */
			st,adc-resolutions = < 0xc 0xa 0x8 0x6 >;                   /* in zephyr\dts\arm\st\l4\stm32l4.dtsi:453 */
			sampling-times = < 0x3 0x7 0xd 0x19 0x30 0x5d 0xf8 0x281 >; /* in zephyr\dts\arm\st\l4\stm32l4.dtsi:454 */
			st,adc-sequencer = "programmable";                          /* in zephyr\dts\arm\st\l4\stm32l4.dtsi:455 */
			st,adc-oversampler = "minimal";                             /* in zephyr\dts\arm\st\l4\stm32l4.dtsi:456 */
			st,adc-internal-regulator = "startup-sw-delay";             /* in zephyr\dts\arm\st\l4\stm32l4.dtsi:457 */
			st,adc-has-deep-powerdown;                                  /* in zephyr\dts\arm\st\l4\stm32l4.dtsi:458 */
			st,adc-has-differential-support;                            /* in zephyr\dts\arm\st\l4\stm32l4.dtsi:459 */
			status = "disabled";                                        /* in zephyr\dts\arm\st\l4\stm32l4.dtsi:460 */
		};

		/* node '/soc/dma@40020000' defined in zephyr\dts\arm\st\l4\stm32l4.dtsi:463 */
		dma1: dma@40020000 {
			compatible = "st,stm32-dma-v2";                                             /* in zephyr\dts\arm\st\l4\stm32l4.dtsi:464 */
			#dma-cells = < 0x3 >;                                                       /* in zephyr\dts\arm\st\l4\stm32l4.dtsi:465 */
			reg = < 0x40020000 0x400 >;                                                 /* in zephyr\dts\arm\st\l4\stm32l4.dtsi:466 */
			interrupts = < 0xb 0x0 0xc 0x0 0xd 0x0 0xe 0x0 0xf 0x0 0x10 0x0 0x11 0x0 >; /* in zephyr\dts\arm\st\l4\stm32l4.dtsi:467 */
			clocks = < &rcc 0x48 0x1 >;                                                 /* in zephyr\dts\arm\st\l4\stm32l4.dtsi:468 */
			dma-requests = < 0x7 >;                                                     /* in zephyr\dts\arm\st\l4\stm32l4.dtsi:469 */
			status = "disabled";                                                        /* in zephyr\dts\arm\st\l4\stm32l4.dtsi:470 */
		};

		/* node '/soc/dma@40020400' defined in zephyr\dts\arm\st\l4\stm32l4.dtsi:473 */
		dma2: dma@40020400 {
			compatible = "st,stm32-dma-v2";                                                  /* in zephyr\dts\arm\st\l4\stm32l4.dtsi:474 */
			#dma-cells = < 0x3 >;                                                            /* in zephyr\dts\arm\st\l4\stm32l4.dtsi:475 */
			reg = < 0x40020400 0x400 >;                                                      /* in zephyr\dts\arm\st\l4\stm32l4.dtsi:476 */
			interrupts = < 0x38 0x0 0x39 0x0 0x3a 0x0 0x3b 0x0 0x3c 0x0 0x44 0x0 0x45 0x0 >; /* in zephyr\dts\arm\st\l4\stm32l4.dtsi:477 */
			clocks = < &rcc 0x48 0x2 >;                                                      /* in zephyr\dts\arm\st\l4\stm32l4.dtsi:478 */
			dma-requests = < 0x7 >;                                                          /* in zephyr\dts\arm\st\l4\stm32l4.dtsi:479 */
			status = "disabled";                                                             /* in zephyr\dts\arm\st\l4\stm32l4.dtsi:480 */
			phandle = < 0x12 >;                                                              /* in zephyr\dts\arm\st\l4\stm32l4_sai.dtsi:16 */
		};

		/* node '/soc/timers@40007c00' defined in zephyr\dts\arm\st\l4\stm32l4.dtsi:483 */
		lptim1: timers@40007c00 {
			compatible = "st,stm32-lptim";     /* in zephyr\dts\arm\st\l4\stm32l4.dtsi:484 */
			clocks = < &rcc 0x58 0x80000000 >; /* in zephyr\dts\arm\st\l4\stm32l4.dtsi:485 */
			resets = < &rctl 0x71f >;          /* in zephyr\dts\arm\st\l4\stm32l4.dtsi:486 */
			#address-cells = < 0x1 >;          /* in zephyr\dts\arm\st\l4\stm32l4.dtsi:487 */
			#size-cells = < 0x0 >;             /* in zephyr\dts\arm\st\l4\stm32l4.dtsi:488 */
			reg = < 0x40007c00 0x400 >;        /* in zephyr\dts\arm\st\l4\stm32l4.dtsi:489 */
			interrupts = < 0x41 0x1 >;         /* in zephyr\dts\arm\st\l4\stm32l4.dtsi:490 */
			interrupt-names = "wakeup";        /* in zephyr\dts\arm\st\l4\stm32l4.dtsi:491 */
			status = "disabled";               /* in zephyr\dts\arm\st\l4\stm32l4.dtsi:492 */
		};

		/* node '/soc/timers@40009400' defined in zephyr\dts\arm\st\l4\stm32l4.dtsi:495 */
		lptim2: timers@40009400 {
			compatible = "st,stm32-lptim"; /* in zephyr\dts\arm\st\l4\stm32l4.dtsi:496 */
			#address-cells = < 0x1 >;      /* in zephyr\dts\arm\st\l4\stm32l4.dtsi:497 */
			#size-cells = < 0x0 >;         /* in zephyr\dts\arm\st\l4\stm32l4.dtsi:498 */
			reg = < 0x40009400 0x400 >;    /* in zephyr\dts\arm\st\l4\stm32l4.dtsi:499 */
			clocks = < &rcc 0x5c 0x20 >;   /* in zephyr\dts\arm\st\l4\stm32l4.dtsi:500 */
			resets = < &rctl 0x785 >;      /* in zephyr\dts\arm\st\l4\stm32l4.dtsi:501 */
			interrupts = < 0x42 0x1 >;     /* in zephyr\dts\arm\st\l4\stm32l4.dtsi:502 */
			interrupt-names = "wakeup";    /* in zephyr\dts\arm\st\l4\stm32l4.dtsi:503 */
			status = "disabled";           /* in zephyr\dts\arm\st\l4\stm32l4.dtsi:504 */
		};

		/* node '/soc/rng@50060800' defined in zephyr\dts\arm\st\l4\stm32l4.dtsi:507 */
		rng: rng@50060800 {
			compatible = "st,stm32-rng";    /* in zephyr\dts\arm\st\l4\stm32l4.dtsi:508 */
			reg = < 0x50060800 0x400 >;     /* in zephyr\dts\arm\st\l4\stm32l4.dtsi:509 */
			interrupts = < 0x50 0x0 >;      /* in zephyr\dts\arm\st\l4\stm32l4.dtsi:510 */
			status = "disabled";            /* in zephyr\dts\arm\st\l4\stm32l4.dtsi:516 */
			clocks = < &rcc 0x4c 0x40000 >,
			         < &rcc 0x5 0x3a0088 >; /* in zephyr\dts\arm\st\l4\stm32l432.dtsi:24 */
		};

		/* node '/soc/power@40007000' defined in zephyr\dts\arm\st\l4\stm32l4.dtsi:519 */
		pwr: power@40007000 {
			compatible = "st,stm32-pwr"; /* in zephyr\dts\arm\st\l4\stm32l4.dtsi:520 */
			reg = < 0x40007000 0x400 >;  /* in zephyr\dts\arm\st\l4\stm32l4.dtsi:521 */
			status = "disabled";         /* in zephyr\dts\arm\st\l4\stm32l4.dtsi:522 */
			wkup-pins-nb = < 0x5 >;      /* in zephyr\dts\arm\st\l4\stm32l4.dtsi:524 */
			wkup-pins-pol;               /* in zephyr\dts\arm\st\l4\stm32l4.dtsi:525 */
			wkup-pins-pupd;              /* in zephyr\dts\arm\st\l4\stm32l4.dtsi:526 */
			#address-cells = < 0x1 >;    /* in zephyr\dts\arm\st\l4\stm32l4.dtsi:528 */
			#size-cells = < 0x0 >;       /* in zephyr\dts\arm\st\l4\stm32l4.dtsi:529 */

			/* node '/soc/power@40007000/wkup-pin@1' defined in zephyr\dts\arm\st\l4\stm32l4.dtsi:531 */
			wkup-pin@1 {
				reg = < 0x1 >; /* in zephyr\dts\arm\st\l4\stm32l4.dtsi:532 */
			};

			/* node '/soc/power@40007000/wkup-pin@2' defined in zephyr\dts\arm\st\l4\stm32l4.dtsi:535 */
			wkup-pin@2 {
				reg = < 0x2 >; /* in zephyr\dts\arm\st\l4\stm32l4.dtsi:536 */
			};

			/* node '/soc/power@40007000/wkup-pin@3' defined in zephyr\dts\arm\st\l4\stm32l4.dtsi:539 */
			wkup-pin@3 {
				reg = < 0x3 >; /* in zephyr\dts\arm\st\l4\stm32l4.dtsi:540 */
			};

			/* node '/soc/power@40007000/wkup-pin@4' defined in zephyr\dts\arm\st\l4\stm32l4.dtsi:543 */
			wkup-pin@4 {
				reg = < 0x4 >; /* in zephyr\dts\arm\st\l4\stm32l4.dtsi:544 */
			};

			/* node '/soc/power@40007000/wkup-pin@5' defined in zephyr\dts\arm\st\l4\stm32l4.dtsi:547 */
			wkup-pin@5 {
				reg = < 0x5 >; /* in zephyr\dts\arm\st\l4\stm32l4.dtsi:548 */
			};
		};

		/* node '/soc/sai1@40015404' defined in zephyr\dts\arm\st\l4\stm32l4_sai.dtsi:9 */
		sai1_a: sai1@40015404 {
			compatible = "st,stm32-sai";      /* in zephyr\dts\arm\st\l4\stm32l4_sai.dtsi:10 */
			#address-cells = < 0x1 >;         /* in zephyr\dts\arm\st\l4\stm32l4_sai.dtsi:11 */
			#size-cells = < 0x0 >;            /* in zephyr\dts\arm\st\l4\stm32l4_sai.dtsi:12 */
			reg = < 0x40015404 0x20 >;        /* in zephyr\dts\arm\st\l4\stm32l4_sai.dtsi:13 */
			clocks = < &rcc 0x60 0x200000 >,
			         < &rcc 0xd 0x360088 >;   /* in zephyr\dts\arm\st\l4\stm32l4_sai.dtsi:14 */
			dmas = < &dma2 0x1 0x1 0x22800 >; /* in zephyr\dts\arm\st\l4\stm32l4_sai.dtsi:16 */
			status = "disabled";              /* in zephyr\dts\arm\st\l4\stm32l4_sai.dtsi:18 */
		};

		/* node '/soc/sai1@40015424' defined in zephyr\dts\arm\st\l4\stm32l4_sai.dtsi:21 */
		sai1_b: sai1@40015424 {
			compatible = "st,stm32-sai";      /* in zephyr\dts\arm\st\l4\stm32l4_sai.dtsi:22 */
			#address-cells = < 0x1 >;         /* in zephyr\dts\arm\st\l4\stm32l4_sai.dtsi:23 */
			#size-cells = < 0x0 >;            /* in zephyr\dts\arm\st\l4\stm32l4_sai.dtsi:24 */
			reg = < 0x40015424 0x20 >;        /* in zephyr\dts\arm\st\l4\stm32l4_sai.dtsi:25 */
			clocks = < &rcc 0x60 0x200000 >,
			         < &rcc 0xd 0x360088 >;   /* in zephyr\dts\arm\st\l4\stm32l4_sai.dtsi:26 */
			dmas = < &dma2 0x2 0x1 0x22800 >; /* in zephyr\dts\arm\st\l4\stm32l4_sai.dtsi:28 */
			status = "disabled";              /* in zephyr\dts\arm\st\l4\stm32l4_sai.dtsi:30 */
		};

		/* node '/soc/spi@40003c00' defined in zephyr\dts\arm\st\l4\stm32l432.dtsi:28 */
		spi3: spi@40003c00 {
			compatible = "st,stm32-spi-fifo",
			             "st,stm32-spi";            /* in zephyr\dts\arm\st\l4\stm32l432.dtsi:29 */
			#address-cells = < 0x1 >;               /* in zephyr\dts\arm\st\l4\stm32l432.dtsi:30 */
			#size-cells = < 0x0 >;                  /* in zephyr\dts\arm\st\l4\stm32l432.dtsi:31 */
			reg = < 0x40003c00 0x400 >;             /* in zephyr\dts\arm\st\l4\stm32l432.dtsi:32 */
			clocks = < &rcc 0x58 0x8000 >;          /* in zephyr\dts\arm\st\l4\stm32l432.dtsi:33 */
			interrupts = < 0x33 0x5 >;              /* in zephyr\dts\arm\st\l4\stm32l432.dtsi:34 */
			st,spi-data-width = "full-4-to-16-bit"; /* in zephyr\dts\arm\st\l4\stm32l432.dtsi:35 */
			status = "disabled";                    /* in zephyr\dts\arm\st\l4\stm32l432.dtsi:36 */
		};

		/* node '/soc/timers@40001400' defined in zephyr\dts\arm\st\l4\stm32l432.dtsi:39 */
		timers7: timers@40001400 {
			compatible = "st,stm32-timers"; /* in zephyr\dts\arm\st\l4\stm32l432.dtsi:40 */
			reg = < 0x40001400 0x400 >;     /* in zephyr\dts\arm\st\l4\stm32l432.dtsi:41 */
			clocks = < &rcc 0x58 0x20 >,
			         < &rcc 0x8 0xff >;     /* in zephyr\dts\arm\st\l4\stm32l432.dtsi:42 */
			resets = < &rctl 0x705 >;       /* in zephyr\dts\arm\st\l4\stm32l432.dtsi:44 */
			interrupts = < 0x37 0x0 >;      /* in zephyr\dts\arm\st\l4\stm32l432.dtsi:45 */
			interrupt-names = "global";     /* in zephyr\dts\arm\st\l4\stm32l432.dtsi:46 */
			st,prescaler = < 0x0 >;         /* in zephyr\dts\arm\st\l4\stm32l432.dtsi:47 */
			status = "disabled";            /* in zephyr\dts\arm\st\l4\stm32l432.dtsi:48 */

			/* node '/soc/timers@40001400/counter' defined in zephyr\dts\arm\st\l4\stm32l432.dtsi:50 */
			counter {
				compatible = "st,stm32-counter"; /* in zephyr\dts\arm\st\l4\stm32l432.dtsi:51 */
				status = "disabled";             /* in zephyr\dts\arm\st\l4\stm32l432.dtsi:52 */
			};
		};

		/* node '/soc/can@40006400' defined in zephyr\dts\arm\st\l4\stm32l432.dtsi:56 */
		can1: can@40006400 {
			compatible = "st,stm32-bxcan";               /* in zephyr\dts\arm\st\l4\stm32l432.dtsi:57 */
			reg = < 0x40006400 0x400 >;                  /* in zephyr\dts\arm\st\l4\stm32l432.dtsi:58 */
			interrupts = < 0x13 0x0 >,
			             < 0x14 0x0 >,
			             < 0x15 0x0 >,
			             < 0x16 0x0 >;                   /* in zephyr\dts\arm\st\l4\stm32l432.dtsi:59 */
			interrupt-names = "TX",
			                  "RX0",
			                  "RX1",
			                  "SCE";                     /* in zephyr\dts\arm\st\l4\stm32l432.dtsi:60 */
			clocks = < &rcc 0x58 0x2000000 >;            /* in zephyr\dts\arm\st\l4\stm32l432.dtsi:61 */
			pinctrl-0 = < &can1_rx_pa11 &can1_tx_pa12 >; /* in zephyr\boards\st\nucleo_l432kc\nucleo_l432kc.dts:102 */
			pinctrl-names = "default";                   /* in zephyr\boards\st\nucleo_l432kc\nucleo_l432kc.dts:103 */
			status = "okay";                             /* in zephyr\boards\st\nucleo_l432kc\nucleo_l432kc.dts:104 */
		};

		/* node '/soc/usb@40006800' defined in zephyr\dts\arm\st\l4\stm32l432.dtsi:65 */
		usb: usb@40006800 {
			compatible = "st,stm32-usb";      /* in zephyr\dts\arm\st\l4\stm32l432.dtsi:66 */
			reg = < 0x40006800 0x40000 >;     /* in zephyr\dts\arm\st\l4\stm32l432.dtsi:67 */
			interrupts = < 0x43 0x0 >;        /* in zephyr\dts\arm\st\l4\stm32l432.dtsi:68 */
			interrupt-names = "usb";          /* in zephyr\dts\arm\st\l4\stm32l432.dtsi:69 */
			num-bidir-endpoints = < 0x8 >;    /* in zephyr\dts\arm\st\l4\stm32l432.dtsi:70 */
			ram-size = < 0x400 >;             /* in zephyr\dts\arm\st\l4\stm32l432.dtsi:71 */
			maximum-speed = "full-speed";     /* in zephyr\dts\arm\st\l4\stm32l432.dtsi:72 */
			phys = < &usb_fs_phy >;           /* in zephyr\dts\arm\st\l4\stm32l432.dtsi:73 */
			clocks = < &rcc 0x58 0x4000000 >,
			         < &rcc 0x5 0x3a0088 >;   /* in zephyr\dts\arm\st\l4\stm32l432.dtsi:74 */
			status = "disabled";              /* in zephyr\dts\arm\st\l4\stm32l432.dtsi:76 */
		};

		/* node '/soc/dac@40007400' defined in zephyr\dts\arm\st\l4\stm32l432.dtsi:79 */
		dac1: dac@40007400 {
			compatible = "st,stm32-dac";       /* in zephyr\dts\arm\st\l4\stm32l432.dtsi:80 */
			reg = < 0x40007400 0x400 >;        /* in zephyr\dts\arm\st\l4\stm32l432.dtsi:81 */
			clocks = < &rcc 0x58 0x20000000 >; /* in zephyr\dts\arm\st\l4\stm32l432.dtsi:82 */
			status = "disabled";               /* in zephyr\dts\arm\st\l4\stm32l432.dtsi:83 */
			#io-channel-cells = < 0x1 >;       /* in zephyr\dts\arm\st\l4\stm32l432.dtsi:84 */
		};
	};

	/* node '/cpus' defined in zephyr\dts\arm\st\l4\stm32l4.dtsi:29 */
	cpus {
		#address-cells = < 0x1 >; /* in zephyr\dts\arm\st\l4\stm32l4.dtsi:30 */
		#size-cells = < 0x0 >;    /* in zephyr\dts\arm\st\l4\stm32l4.dtsi:31 */

		/* node '/cpus/cpu@0' defined in zephyr\dts\arm\st\l4\stm32l4.dtsi:33 */
		cpu0: cpu@0 {
			device_type = "cpu";                         /* in zephyr\dts\arm\st\l4\stm32l4.dtsi:34 */
			compatible = "arm,cortex-m4f";               /* in zephyr\dts\arm\st\l4\stm32l4.dtsi:35 */
			reg = < 0x0 >;                               /* in zephyr\dts\arm\st\l4\stm32l4.dtsi:36 */
			cpu-power-states = < &stop0 &stop1 &stop2 >; /* in zephyr\dts\arm\st\l4\stm32l4.dtsi:37 */
		};

		/* node '/cpus/power-states' defined in zephyr\dts\arm\st\l4\stm32l4.dtsi:40 */
		power-states {

			/* node '/cpus/power-states/state0' defined in zephyr\dts\arm\st\l4\stm32l4.dtsi:41 */
			stop0: state0 {
				compatible = "zephyr,power-state";    /* in zephyr\dts\arm\st\l4\stm32l4.dtsi:42 */
				power-state-name = "suspend-to-idle"; /* in zephyr\dts\arm\st\l4\stm32l4.dtsi:43 */
				substate-id = < 0x1 >;                /* in zephyr\dts\arm\st\l4\stm32l4.dtsi:44 */
				min-residency-us = < 0x1f4 >;         /* in zephyr\dts\arm\st\l4\stm32l4.dtsi:45 */
				phandle = < 0x16 >;                   /* in zephyr\dts\arm\st\l4\stm32l4.dtsi:37 */
			};

			/* node '/cpus/power-states/state1' defined in zephyr\dts\arm\st\l4\stm32l4.dtsi:48 */
			stop1: state1 {
				compatible = "zephyr,power-state";    /* in zephyr\dts\arm\st\l4\stm32l4.dtsi:49 */
				power-state-name = "suspend-to-idle"; /* in zephyr\dts\arm\st\l4\stm32l4.dtsi:50 */
				substate-id = < 0x2 >;                /* in zephyr\dts\arm\st\l4\stm32l4.dtsi:51 */
				min-residency-us = < 0x2bc >;         /* in zephyr\dts\arm\st\l4\stm32l4.dtsi:52 */
				phandle = < 0x17 >;                   /* in zephyr\dts\arm\st\l4\stm32l4.dtsi:37 */
			};

			/* node '/cpus/power-states/state2' defined in zephyr\dts\arm\st\l4\stm32l4.dtsi:55 */
			stop2: state2 {
				compatible = "zephyr,power-state";    /* in zephyr\dts\arm\st\l4\stm32l4.dtsi:56 */
				power-state-name = "suspend-to-idle"; /* in zephyr\dts\arm\st\l4\stm32l4.dtsi:57 */
				substate-id = < 0x3 >;                /* in zephyr\dts\arm\st\l4\stm32l4.dtsi:58 */
				min-residency-us = < 0x3e8 >;         /* in zephyr\dts\arm\st\l4\stm32l4.dtsi:59 */
				phandle = < 0x18 >;                   /* in zephyr\dts\arm\st\l4\stm32l4.dtsi:37 */
			};
		};
	};

	/* node '/memory@20000000' defined in zephyr\dts\arm\st\l4\stm32l4.dtsi:64 */
	sram0: memory@20000000 {
		compatible = "zephyr,memory-region",
		             "mmio-sram";            /* in zephyr\dts\arm\st\l4\stm32l4.dtsi:65 */
		zephyr,memory-region = "SRAM0";      /* in zephyr\dts\arm\st\l4\stm32l4.dtsi:66 */
		reg = < 0x20000000 0x10000 >;        /* in zephyr\dts\arm\st\l4\stm32l432Xc.dtsi:10 */
	};

	/* node '/clocks' defined in zephyr\dts\arm\st\l4\stm32l4.dtsi:69 */
	clocks {

		/* node '/clocks/clk-hse' defined in zephyr\dts\arm\st\l4\stm32l4.dtsi:70 */
		clk_hse: clk-hse {
			#clock-cells = < 0x0 >;            /* in zephyr\dts\arm\st\l4\stm32l4.dtsi:71 */
			compatible = "st,stm32-hse-clock"; /* in zephyr\dts\arm\st\l4\stm32l4.dtsi:72 */
			status = "disabled";               /* in zephyr\dts\arm\st\l4\stm32l4.dtsi:73 */
		};

		/* node '/clocks/clk-hsi' defined in zephyr\dts\arm\st\l4\stm32l4.dtsi:76 */
		clk_hsi: clk-hsi {
			#clock-cells = < 0x0 >;         /* in zephyr\dts\arm\st\l4\stm32l4.dtsi:77 */
			compatible = "fixed-clock";     /* in zephyr\dts\arm\st\l4\stm32l4.dtsi:78 */
			clock-frequency = < 0xf42400 >; /* in zephyr\dts\arm\st\l4\stm32l4.dtsi:79 */
			status = "okay";                /* in zephyr\boards\st\nucleo_l432kc\nucleo_l432kc.dts:43 */
			phandle = < 0x19 >;             /* in zephyr\boards\st\nucleo_l432kc\nucleo_l432kc.dts:52 */
		};

		/* node '/clocks/clk-msi' defined in zephyr\dts\arm\st\l4\stm32l4.dtsi:83 */
		clk_msi: clk-msi {
			#clock-cells = < 0x0 >;            /* in zephyr\dts\arm\st\l4\stm32l4.dtsi:84 */
			compatible = "st,stm32-msi-clock"; /* in zephyr\dts\arm\st\l4\stm32l4.dtsi:85 */
			msi-range = < 0x6 >;               /* in zephyr\dts\arm\st\l4\stm32l4.dtsi:86 */
			status = "disabled";               /* in zephyr\dts\arm\st\l4\stm32l4.dtsi:87 */
		};

		/* node '/clocks/clk-lse' defined in zephyr\dts\arm\st\l4\stm32l4.dtsi:90 */
		clk_lse: clk-lse {
			#clock-cells = < 0x0 >;            /* in zephyr\dts\arm\st\l4\stm32l4.dtsi:91 */
			compatible = "st,stm32-lse-clock"; /* in zephyr\dts\arm\st\l4\stm32l4.dtsi:92 */
			clock-frequency = < 0x8000 >;      /* in zephyr\dts\arm\st\l4\stm32l4.dtsi:93 */
			driving-capability = < 0x0 >;      /* in zephyr\dts\arm\st\l4\stm32l4.dtsi:94 */
			status = "disabled";               /* in zephyr\dts\arm\st\l4\stm32l4.dtsi:95 */
		};

		/* node '/clocks/clk-lsi' defined in zephyr\dts\arm\st\l4\stm32l4.dtsi:98 */
		clk_lsi: clk-lsi {
			#clock-cells = < 0x0 >;       /* in zephyr\dts\arm\st\l4\stm32l4.dtsi:99 */
			compatible = "fixed-clock";   /* in zephyr\dts\arm\st\l4\stm32l4.dtsi:100 */
			clock-frequency = < 0x7d00 >; /* in zephyr\dts\arm\st\l4\stm32l4.dtsi:101 */
			status = "okay";              /* in zephyr\boards\st\nucleo_l432kc\nucleo_l432kc.dts:39 */
		};

		/* node '/clocks/pll' defined in zephyr\dts\arm\st\l4\stm32l4.dtsi:105 */
		pll: pll {
			#clock-cells = < 0x0 >;              /* in zephyr\dts\arm\st\l4\stm32l4.dtsi:106 */
			compatible = "st,stm32l4-pll-clock"; /* in zephyr\dts\arm\st\l4\stm32l4.dtsi:107 */
			div-m = < 0x1 >;                     /* in zephyr\boards\st\nucleo_l432kc\nucleo_l432kc.dts:47 */
			mul-n = < 0x14 >;                    /* in zephyr\boards\st\nucleo_l432kc\nucleo_l432kc.dts:48 */
			div-p = < 0x7 >;                     /* in zephyr\boards\st\nucleo_l432kc\nucleo_l432kc.dts:49 */
			div-q = < 0x2 >;                     /* in zephyr\boards\st\nucleo_l432kc\nucleo_l432kc.dts:50 */
			div-r = < 0x4 >;                     /* in zephyr\boards\st\nucleo_l432kc\nucleo_l432kc.dts:51 */
			clocks = < &clk_hsi >;               /* in zephyr\boards\st\nucleo_l432kc\nucleo_l432kc.dts:52 */
			status = "okay";                     /* in zephyr\boards\st\nucleo_l432kc\nucleo_l432kc.dts:53 */
			phandle = < 0x3 >;                   /* in zephyr\boards\st\nucleo_l432kc\nucleo_l432kc.dts:57 */
		};

		/* node '/clocks/pllsai1' defined in zephyr\dts\arm\st\l4\stm32l4.dtsi:111 */
		pllsai1: pllsai1 {
			#clock-cells = < 0x0 >;                 /* in zephyr\dts\arm\st\l4\stm32l4.dtsi:112 */
			compatible = "st,stm32l4-pllsai-clock"; /* in zephyr\dts\arm\st\l4\stm32l4.dtsi:113 */
			status = "disabled";                    /* in zephyr\dts\arm\st\l4\stm32l4.dtsi:114 */
		};

		/* node '/clocks/clk-hsi48' defined in zephyr\dts\arm\st\l4\stm32l432.dtsi:12 */
		clk_hsi48: clk-hsi48 {
			#clock-cells = < 0x0 >;          /* in zephyr\dts\arm\st\l4\stm32l432.dtsi:13 */
			compatible = "fixed-clock";      /* in zephyr\dts\arm\st\l4\stm32l432.dtsi:14 */
			clock-frequency = < 0x2dc6c00 >; /* in zephyr\dts\arm\st\l4\stm32l432.dtsi:15 */
			status = "disabled";             /* in zephyr\dts\arm\st\l4\stm32l432.dtsi:16 */
		};
	};

	/* node '/mcos' defined in zephyr\dts\arm\st\l4\stm32l4.dtsi:118 */
	mcos {

		/* node '/mcos/mco1' defined in zephyr\dts\arm\st\l4\stm32l4.dtsi:119 */
		mco1: mco1 {
			compatible = "st,stm32-clock-mco"; /* in zephyr\dts\arm\st\l4\stm32l4.dtsi:120 */
			status = "disabled";               /* in zephyr\dts\arm\st\l4\stm32l4.dtsi:121 */
		};
	};

	/* node '/dietemp' defined in zephyr\dts\arm\st\l4\stm32l4.dtsi:553 */
	die_temp: dietemp {
		compatible = "st,stm32-temp-cal"; /* in zephyr\dts\arm\st\l4\stm32l4.dtsi:554 */
		ts-cal1-addr = < 0x1fff75a8 >;    /* in zephyr\dts\arm\st\l4\stm32l4.dtsi:555 */
		ts-cal2-addr = < 0x1fff75ca >;    /* in zephyr\dts\arm\st\l4\stm32l4.dtsi:556 */
		ts-cal1-temp = < 0x1e >;          /* in zephyr\dts\arm\st\l4\stm32l4.dtsi:557 */
		ts-cal2-temp = < 0x82 >;          /* in zephyr\dts\arm\st\l4\stm32l4.dtsi:558 */
		ts-cal-vrefanalog = < 0xbb8 >;    /* in zephyr\dts\arm\st\l4\stm32l4.dtsi:559 */
		io-channels = < &adc1 0x11 >;     /* in zephyr\dts\arm\st\l4\stm32l4.dtsi:560 */
		status = "disabled";              /* in zephyr\dts\arm\st\l4\stm32l4.dtsi:561 */
	};

	/* node '/vref' defined in zephyr\dts\arm\st\l4\stm32l4.dtsi:564 */
	vref: vref {
		compatible = "st,stm32-vref";      /* in zephyr\dts\arm\st\l4\stm32l4.dtsi:565 */
		vrefint-cal-addr = < 0x1fff75aa >; /* in zephyr\dts\arm\st\l4\stm32l4.dtsi:566 */
		vrefint-cal-mv = < 0xbb8 >;        /* in zephyr\dts\arm\st\l4\stm32l4.dtsi:567 */
		io-channels = < &adc1 0x0 >;       /* in zephyr\dts\arm\st\l4\stm32l4.dtsi:568 */
		status = "disabled";               /* in zephyr\dts\arm\st\l4\stm32l4.dtsi:569 */
	};

	/* node '/vbat' defined in zephyr\dts\arm\st\l4\stm32l4.dtsi:572 */
	vbat: vbat {
		compatible = "st,stm32-vbat"; /* in zephyr\dts\arm\st\l4\stm32l4.dtsi:573 */
		ratio = < 0x3 >;              /* in zephyr\dts\arm\st\l4\stm32l4.dtsi:574 */
		io-channels = < &adc1 0x12 >; /* in zephyr\dts\arm\st\l4\stm32l4.dtsi:575 */
		status = "disabled";          /* in zephyr\dts\arm\st\l4\stm32l4.dtsi:576 */
	};

	/* node '/smbus1' defined in zephyr\dts\arm\st\l4\stm32l4.dtsi:579 */
	smbus1: smbus1 {
		compatible = "st,stm32-smbus"; /* in zephyr\dts\arm\st\l4\stm32l4.dtsi:580 */
		#address-cells = < 0x1 >;      /* in zephyr\dts\arm\st\l4\stm32l4.dtsi:581 */
		#size-cells = < 0x0 >;         /* in zephyr\dts\arm\st\l4\stm32l4.dtsi:582 */
		i2c = < &i2c1 >;               /* in zephyr\dts\arm\st\l4\stm32l4.dtsi:583 */
		status = "disabled";           /* in zephyr\dts\arm\st\l4\stm32l4.dtsi:584 */
	};

	/* node '/smbus3' defined in zephyr\dts\arm\st\l4\stm32l4.dtsi:587 */
	smbus3: smbus3 {
		compatible = "st,stm32-smbus"; /* in zephyr\dts\arm\st\l4\stm32l4.dtsi:588 */
		#address-cells = < 0x1 >;      /* in zephyr\dts\arm\st\l4\stm32l4.dtsi:589 */
		#size-cells = < 0x0 >;         /* in zephyr\dts\arm\st\l4\stm32l4.dtsi:590 */
		i2c = < &i2c3 >;               /* in zephyr\dts\arm\st\l4\stm32l4.dtsi:591 */
		status = "disabled";           /* in zephyr\dts\arm\st\l4\stm32l4.dtsi:592 */
	};

	/* node '/usbphy' defined in zephyr\dts\arm\st\l4\stm32l432.dtsi:96 */
	usb_fs_phy: usbphy {
		compatible = "usb-nop-xceiv"; /* in zephyr\dts\arm\st\l4\stm32l432.dtsi:97 */
		#phy-cells = < 0x0 >;         /* in zephyr\dts\arm\st\l4\stm32l432.dtsi:98 */
		phandle = < 0x15 >;           /* in zephyr\dts\arm\st\l4\stm32l432.dtsi:73 */
	};

	/* node '/connector' defined in zephyr\boards\st\nucleo_l432kc\arduino_nano_connector.dtsi:11 */
	arduino_header: connector {
		compatible = "arduino-nano-header";        /* in zephyr\boards\st\nucleo_l432kc\arduino_nano_connector.dtsi:12 */
		#gpio-cells = < 0x2 >;                     /* in zephyr\boards\st\nucleo_l432kc\arduino_nano_connector.dtsi:13 */
		gpio-map-mask = < 0xffffffff 0xffffffc0 >; /* in zephyr\boards\st\nucleo_l432kc\arduino_nano_connector.dtsi:14 */
		gpio-map-pass-thru = < 0x0 0x3f >;         /* in zephyr\boards\st\nucleo_l432kc\arduino_nano_connector.dtsi:15 */
		gpio-map = < 0x0 0x0 &gpioa 0xa 0x0 >,
		           < 0x1 0x0 &gpioa 0x9 0x0 >,
		           < 0x2 0x0 &gpioa 0xc 0x0 >,
		           < 0x3 0x0 &gpiob 0x0 0x0 >,
		           < 0x4 0x0 &gpiob 0x7 0x0 >,
		           < 0x5 0x0 &gpioa 0x6 0x0 >,
		           < 0x6 0x0 &gpiob 0x1 0x0 >,
		           < 0x7 0x0 &gpioc 0xe 0x0 >,
		           < 0x8 0x0 &gpioc 0xf 0x0 >,
		           < 0x9 0x0 &gpioa 0x8 0x0 >,
		           < 0xa 0x0 &gpioa 0xb 0x0 >,
		           < 0xb 0x0 &gpiob 0x5 0x0 >,
		           < 0xc 0x0 &gpiob 0x4 0x0 >,
		           < 0xd 0x0 &gpiob 0x3 0x0 >,
		           < 0xe 0x0 &gpioa 0x0 0x0 >,
		           < 0xf 0x0 &gpioa 0x1 0x0 >,
		           < 0x10 0x0 &gpioa 0x3 0x0 >,
		           < 0x13 0x0 &gpioa 0x4 0x0 >,
		           < 0x12 0x0 &gpioa 0x5 0x0 >,
		           < 0x13 0x0 &gpioa 0x6 0x0 >,
		           < 0x14 0x0 &gpioa 0x7 0x0 >,
		           < 0x15 0x0 &gpioa 0x2 0x0 >;    /* in zephyr\boards\st\nucleo_l432kc\arduino_nano_connector.dtsi:16 */
	};

	/* node '/leds' defined in zephyr\boards\st\nucleo_l432kc\nucleo_l432kc.dts:24 */
	leds: leds {
		compatible = "gpio-leds"; /* in zephyr\boards\st\nucleo_l432kc\nucleo_l432kc.dts:25 */

		/* node '/leds/led_0' defined in zephyr\boards\st\nucleo_l432kc\nucleo_l432kc.dts:27 */
		green_led: led_0 {
			gpios = < &gpiob 0x3 0x0 >; /* in zephyr\boards\st\nucleo_l432kc\nucleo_l432kc.dts:28 */
			label = "User LD3";         /* in zephyr\boards\st\nucleo_l432kc\nucleo_l432kc.dts:29 */
		};
	};
};
